# STM32WL30 register map
File version: 1.1
CPU: CM0+ r0p0, little endian, MPU, no FPU, 4 interrupt priority bits
Registers are 32-bit, read-write, reset 0x0 unless marked. A register's access mark holds for its fields unless they carry their own. Offsets are from the block's base; [hi:lo] are bit positions.

## IWDG
Base 0x40003000
0x00 IWDG_KR
  [15:0] KEY wo — Key value. Software can only write these bits. Reading returns the reset value. These bits must be written by software at regular intervals with the key value 0xAAAA, otherwise the watchdog generates a reset when the counter reaches 0. Writing the key value 0x5555 to enables access to the IWDG_PR, IWDG_RLR and IWDG_WINR registers. Writing the key value CCCCh starts the watchdog
0x04 IWDG_PR
  [2:0] PR — Prescaler divider. Set and reset by software. These bits are write access protected. They are written by software to select the prescaler divider feeding the counter clock. PVU bit of IWDG_SR must be reset in order to be able to change the prescaler divider. 000: divider/4 001: divider/8 010: divider/16 011: divider/32 100: divider/64 101: divider/128 110: divider/256 111: divider/256
0x08 IWDG_RLR reset 0xFFF
  [11:0] RL — Watchdog counter reload value. Set and reset by software. These bits are write access protected. They are written by software to define the value to be loaded in the watchdog counter each time the value 0xAAAA is written in the IWDG_KR register. The watchdog counter counts down from this value. The timeout period is a function of this value and the clock prescaler. The RVU bit in the IWDG_SR register must be reset in order to be able to change the reload value.
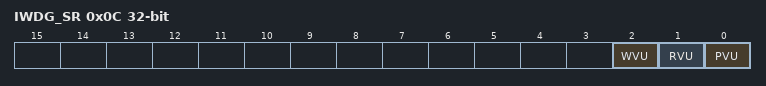
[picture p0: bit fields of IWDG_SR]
0x0C IWDG_SR ro
  [2] WVU — Watchdog counter window value update. Read only bit. This bit is set by hardware to indicate that an update of the window value is ongoing. It is reset by hardware when the reload value update operation is completed in the VDD voltage domain (takes up to 5 RC 40 kHz cycles). Window value can be updated only when WVU bit is reset. This bit is generated only if generic 'window' = 1
  [1] RVU — Watchdog counter reload value update. Read only bit. This bit is set by hardware to indicate that an update of the reload value is ongoing. It is reset by hardware when the reload value update operation is completed in the VDD voltage domain (takes up to 5 RC 40 kHz cycles). Reload value can be updated only when RVU bit is reset
  [0] PVU — Watchdog prescaler value update. Read only bit. This bit is set by hardware to indicate that an update of the prescaler value is ongoing. It is reset by hardware when the prescaler update operation is completed in the VDD voltage domain (takes up to 5 RC 40 kHz cycles). Prescaler value can be updated only when PVU bit is reset
0x10 IWDG_WINR reset 0xFFF
  [11:0] WIN — Watchdog counter window value. Set and reset by software. These bits are write access protected. These bits contain the high limit of the window value to be compared to the downcounter. To prevent a reset, the downcounter must be reloaded when its value is lower than the window register value and greater than 0x0 The WVU bit in the IWDG_SR register must be reset in order to be able to change the reload value.

## MISC
Base 0x49000700
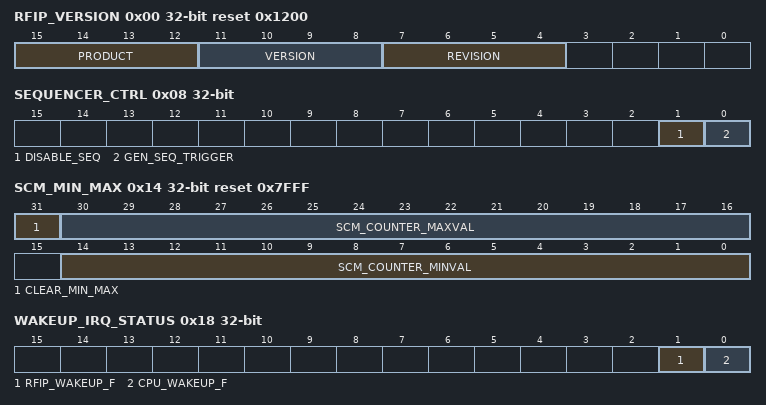
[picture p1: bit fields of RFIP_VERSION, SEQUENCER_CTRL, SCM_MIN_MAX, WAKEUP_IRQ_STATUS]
0x00 RFIP_VERSION ro reset 0x1200
  [15:12] PRODUCT — Used for major upgrades (new protocols support / new features)
  [11:8] VERSION — Version of the MR_SubG (to be used for cut upgrades)
  [7:4] REVISION — Revision of the MR_SubG (to be used for metal fixes)
0x04 RRM_UDRA_CTRL wo
  [0] RRM_CMD_REQ — Action bit: write 1 to request a RRM-UDRA command.
0x08 SEQUENCER_CTRL
  [1] DISABLE_SEQ — Enable/disable the Sequencer
  [0] GEN_SEQ_TRIGGER wo — Action bit: write 1 to generate a trigger event on Sequencer.
0x0C ABSOLUTE_TIME ro
  [31:0] ABSOLUTE_TIME — Indicate the interpolated absolute.
0x10 SCM_COUNTER_VAL ro
  [14:0] SCM_COUNTER_CURRVAL — Slow Clock Measurement: number of 16 MHz clock cycles contained in 32 slow clock periods.
0x14 SCM_MIN_MAX reset 0x7FFF
  [31] CLEAR_MIN_MAX wo — Write 1' to clear the SCM_COUNTER_MINVAL and SCM_COUNTER_MAXVAL bit fields.
  [30:16] SCM_COUNTER_MAXVAL ro — Slow Clock Measurement: maximum SCM_COUNTER value seen since the counter is ON and since last clear request.
  [14:0] SCM_COUNTER_MINVAL ro — Slow Clock Measurement: minimum SCM_COUNTER value seen since the counter is ON and since last clear request.
0x18 WAKEUP_IRQ_STATUS
  [1] RFIP_WAKEUP_F — Set when the interpolated absolute time matches the RFIP_WAKEUPTIME while WAKEUP_CTRL.
  [0] CPU_WAKEUP_F — Set when the interpolated absolute time matches the CPU_WAKEUPTIME while WAKEUP_CTRL.

## Notices in the file
Copyright (c) 2025 STMicroelectronics.
SPDX-License-Identifier: Apache-2.0
Licensed under the Apache License, Version 2.0 (the "License");
you may not use this file except in compliance with the License.
You may obtain a copy of the License at
http://www.apache.org/licenses/LICENSE-2.0
Unless required by applicable law or agreed to in writing, software
distributed under the License is distributed on an "AS IS" BASIS,
WITHOUT WARRANTIES OR CONDITIONS OF ANY KIND, either express or implied.
See the License for the specific language governing permissions and
limitations under the License.
